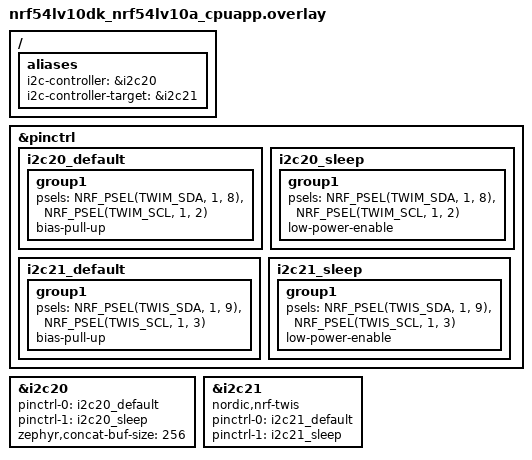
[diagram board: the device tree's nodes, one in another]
/*
 * Copyright (c) 2026 Nordic Semiconductor ASA
 *
 * SPDX-License-Identifier: Apache-2.0
 */

/*
 * SDA = P1.8 and P1.9
 * SCL = P1.2 and P1.3
 */

/ {
	aliases {
		i2c-controller = &i2c20;
		i2c-controller-target = &i2c21;
	};
};

&pinctrl {
	i2c20_default: i2c20_default {
		group1 {
			psels = <NRF_PSEL(TWIM_SDA, 1, 8)>,
				<NRF_PSEL(TWIM_SCL, 1, 2)>;
			bias-pull-up;
		};
	};

	i2c20_sleep: i2c20_sleep {
		group1 {
			psels = <NRF_PSEL(TWIM_SDA, 1, 8)>,
				<NRF_PSEL(TWIM_SCL, 1, 2)>;
			low-power-enable;
		};
	};

	i2c21_default: i2c21_default {
		group1 {
			psels = <NRF_PSEL(TWIS_SDA, 1, 9)>,
				<NRF_PSEL(TWIS_SCL, 1, 3)>;
			bias-pull-up;
		};
	};

	i2c21_sleep: i2c21_sleep {
		group1 {
			psels = <NRF_PSEL(TWIS_SDA, 1, 9)>,
				<NRF_PSEL(TWIS_SCL, 1, 3)>;
			low-power-enable;
		};
	};
};

&i2c20 {
	pinctrl-0 = <&i2c20_default>;
	pinctrl-1 = <&i2c20_sleep>;
	pinctrl-names = "default", "sleep";
	zephyr,concat-buf-size = <256>;
	status = "okay";
};

&i2c21 {
	compatible = "nordic,nrf-twis";
	pinctrl-0 = <&i2c21_default>;
	pinctrl-1 = <&i2c21_sleep>;
	pinctrl-names = "default", "sleep";
	status = "okay";
};
